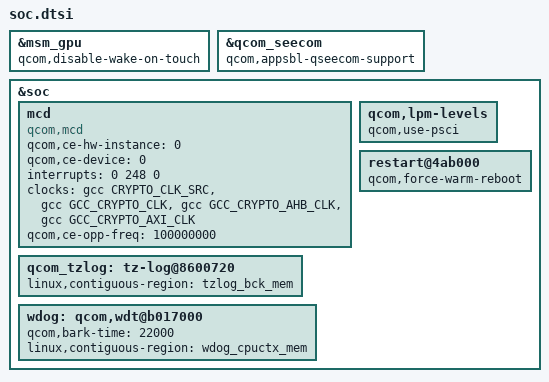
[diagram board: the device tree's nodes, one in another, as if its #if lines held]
&msm_gpu {
	qcom,disable-wake-on-touch;
};

&qcom_seecom {
	qcom,appsbl-qseecom-support;
};

&soc {
#ifdef SOC_MSM8917
	mcd {
		compatible = "qcom,mcd";
		qcom,ce-hw-instance = <0>;
		qcom,ce-device = <0>;
		interrupts = <0 248 0>;
		interrupt-names = "mcd_irq";
		clocks = <&gcc CRYPTO_CLK_SRC>,
			 <&gcc GCC_CRYPTO_CLK>,
			 <&gcc GCC_CRYPTO_AHB_CLK>,
			 <&gcc GCC_CRYPTO_AXI_CLK>;
		clock-names = "core_clk_src", "core_clk",
				"iface_clk", "bus_clk";
		qcom,ce-opp-freq = <100000000>;
	};
#endif

	qcom,lpm-levels {
		qcom,use-psci;
	};

#ifdef SOC_MSM8917
	qcom_tzlog: tz-log@8600720
#else
	qcom_tzlog: tz-log@08600720
#endif
	{
		status = "okay";
		linux,contiguous-region = <&tzlog_bck_mem>;
	};

	restart@4ab000 {
		qcom,force-warm-reboot;
	};

	wdog: qcom,wdt@b017000 {
		qcom,bark-time = <22000>;
		linux,contiguous-region = <&wdog_cpuctx_mem>;
	};
};
